CM_ "AUTOGENERATED FILE, DO NOT EDIT"

CM_ "Imported file _toyota_2017.dbc starts here"
VERSION ""

NS_ :

BS_:

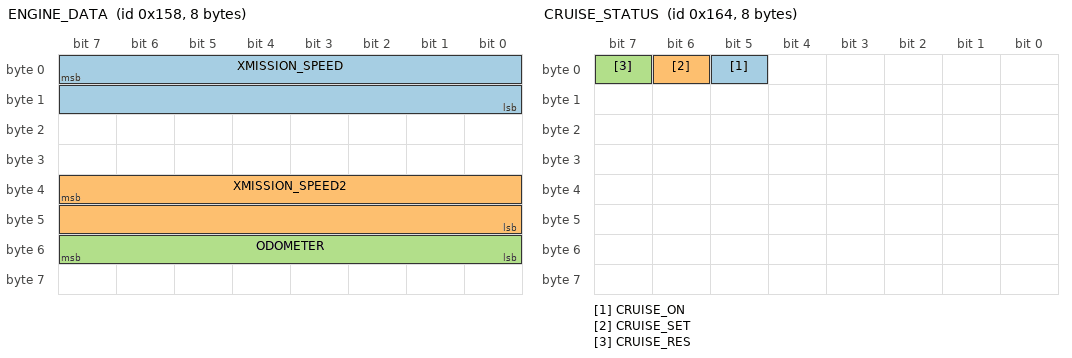
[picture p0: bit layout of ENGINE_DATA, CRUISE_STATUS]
BO_ 344 ENGINE_DATA: 8 PCM
 SG_ XMISSION_SPEED : 7|16@0+ (0.01,0) [0|250] "kph" EON
 SG_ XMISSION_SPEED2 : 39|16@0+ (0.01,0) [0|250] "kph" EON
 SG_ ODOMETER : 55|8@0+ (10,0) [0|2550] "m" XXX

BO_ 353 DSU_SPEED: 7 XXX
 SG_ FORWARD_SPEED : 15|16@0- (0.00390625,-30) [0|255] "kph" XXX

BO_ 356 CRUISE_STATUS: 8 XXX
 SG_ CRUISE_ON : 5|1@0+ (1,0) [0|1] "" XXX
 SG_ CRUISE_SET : 6|1@0+ (1,0) [0|1] "" XXX
 SG_ CRUISE_RES : 7|1@0+ (1,0) [0|1] "" XXX

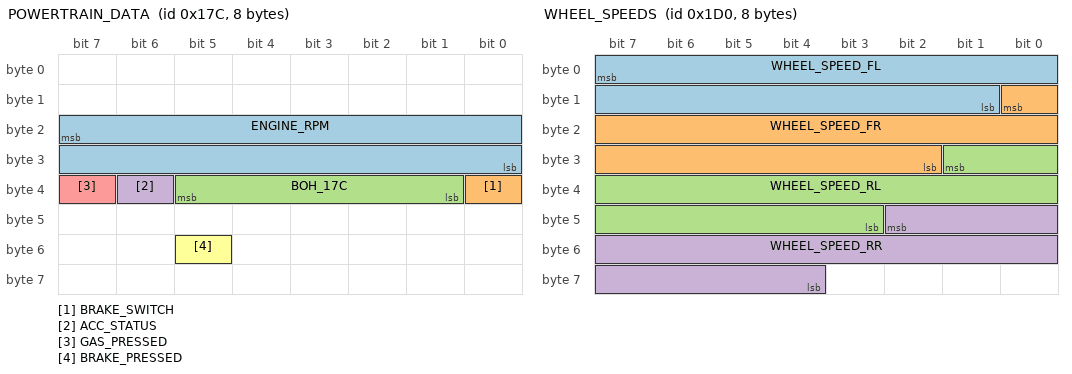
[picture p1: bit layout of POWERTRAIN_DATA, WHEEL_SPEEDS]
BO_ 380 POWERTRAIN_DATA: 8 PCM
 SG_ ENGINE_RPM : 23|16@0+ (1,0) [0|15000] "rpm" EON
 SG_ BRAKE_SWITCH : 32|1@0+ (1,0) [0|1] "" EON
 SG_ BOH_17C : 37|5@0+ (1,0) [0|1] "" EON
 SG_ ACC_STATUS : 38|1@0+ (1,0) [0|1] "" EON
 SG_ GAS_PRESSED : 39|1@0+ (1,0) [0|1] "" EON
 SG_ BRAKE_PRESSED : 53|1@0+ (1,0) [0|1] "" EON

BO_ 398 STEERING_EPS_DATA: 3 XXX
 SG_ STEERING_RATEDEG : 1|10@0+ (1,0) [0|1023] "" XXX

BO_ 452 ENGINE_RPM: 8 CGW
 SG_ RPM : 7|16@0- (0.78125,0) [0|0] "rpm" SCS

BO_ 464 WHEEL_SPEEDS: 8 VSA
 SG_ WHEEL_SPEED_FL : 7|15@0+ (0.01,0) [0|250] "kph" EON
 SG_ WHEEL_SPEED_FR : 8|15@0+ (0.01,0) [0|250] "kph" EON
 SG_ WHEEL_SPEED_RL : 25|15@0+ (0.01,0) [0|250] "kph" EON
 SG_ WHEEL_SPEED_RR : 42|15@0+ (0.01,0) [0|250] "kph" EON

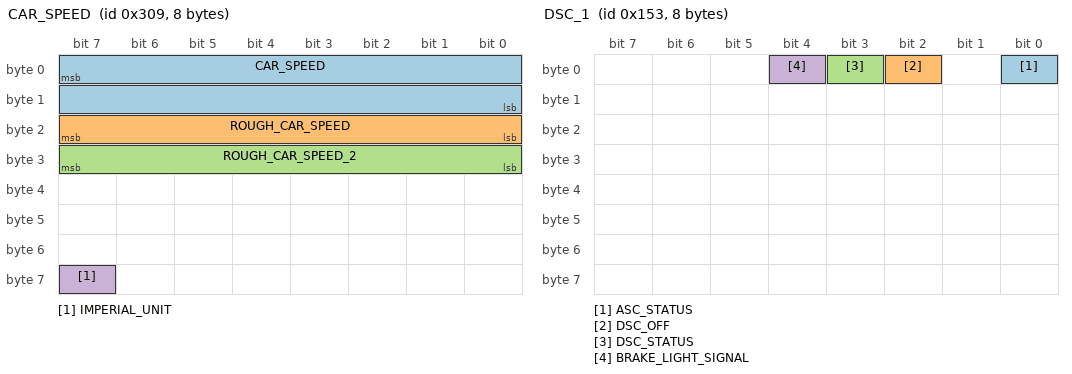
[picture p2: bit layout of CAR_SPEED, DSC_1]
BO_ 777 CAR_SPEED: 8 PCM
 SG_ CAR_SPEED : 7|16@0+ (0.01,0) [0|65535] "kph" XXX
 SG_ ROUGH_CAR_SPEED : 23|8@0+ (1,0) [0|255] "mph" XXX
 SG_ ROUGH_CAR_SPEED_2 : 31|8@0+ (1,0) [0|255] "mph" XXX
 SG_ IMPERIAL_UNIT : 63|1@0+ (1,0) [0|1] "" XXX

VAL_ 466 CRUISE_STATE 8 "active" 7 "standstill" 1 "off";
VAL_ 467 LOW_SPEED_LOCKOUT 2 "low speed locked" 1 "ok";
VAL_ 614 STATE 3 "enabled" 1 "disabled";
VAL_ 614 DIRECTION_CMD 3 "right" 2 "center" 1 "left";
VAL_ 643 STATE 0 "normal" 1 "adaptive_cruise_control" 3 "emergency_braking";
VAL_ 921 CRUISE_CONTROL_STATE 2 "disabled" 11 "hold" 10 "hold_waiting_user_cmd" 6 "enabled" 5 "faulted";
VAL_ 1042 LDA_ALERT 3 "hold with continuous beep" 2 "LDA unavailable" 1 "hold" 0 "none";
VAL_ 1042 BARRIERS 3 "both" 2 "right" 1 "left" 0 "none";
VAL_ 1042 RIGHT_LINE 3 "orange" 2 "faded" 1 "solid" 0 "none";
VAL_ 1042 LEFT_LINE 3 "orange" 2 "faded" 1 "solid" 0 "none";
VAL_ 1553 UNITS 1 "km" 2 "miles";
VAL_ 1556 TURN_SIGNALS 3 "none" 2 "right" 1 "left";
VAL_ 1161 TSGN1 1 "speed sign" 0 "none";
VAL_ 1161 TSGN2 1 "speed sign" 0 "none";
VAL_ 1161 SPLSGN2 15 "conditional blank" 4 "wet road" 5 "rain" 0 "none";
VAL_ 1162 TSGN3 0 "none" 1 "speed sign" 2 "0 unlimited" 7 "unlimited" 16 "highway" 17 "no highway" 18 "motorway" 19 "no motorway" 20 "in city" 21 "outside city" 22 "pedestrian area" 23 "no pedestrian area" 65 "no overtaking left" 66 "no overtaking right" 67 "overtaking allowed again" 129 "no entry";
VAL_ 1162 SPLSGN3 15 "conditional blank" 4 "wet road" 5 "rain" 0 "none";

CM_ "CHFFR_METRIC 37 STEER_ANGLE STEER_ANGLE 0.36 180";

CM_ "toyota_corolla_2017_pt.dbc starts here"

BO_ 339 DSC_1: 8 XXX
 SG_ ASC_STATUS : 0|1@1+ (1,0) [0|3] "" XXX
 SG_ DSC_OFF : 2|1@1+ (1,0) [0|3] "" XXX
 SG_ DSC_STATUS : 3|1@0+ (1,0) [0|3] "" XXX
 SG_ BRAKE_LIGHT_SIGNAL : 4|1@0+ (1,0) [0|3] "" XXX

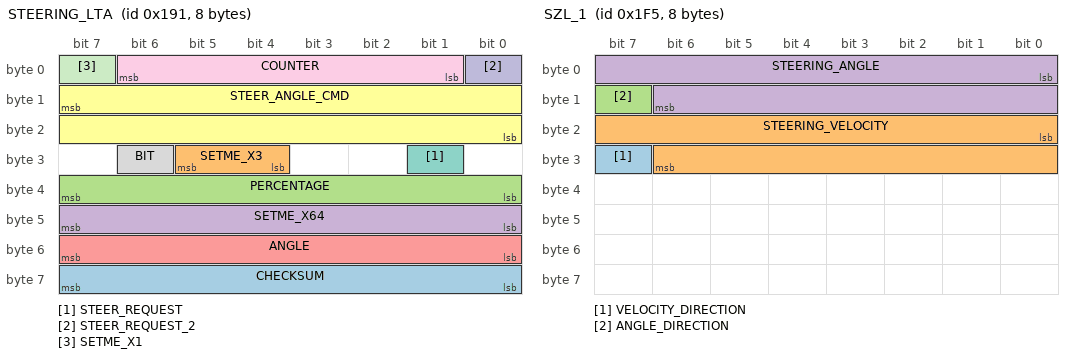
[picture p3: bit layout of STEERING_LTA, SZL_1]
BO_ 401 STEERING_LTA: 8 XXX
 SG_ CHECKSUM : 63|8@0+ (1,0) [0|255] "" XXX
 SG_ SETME_X3 : 29|2@0+ (1,0) [0|3] "" XXX
 SG_ PERCENTAGE : 39|8@0+ (1,0) [0|255] "" XXX
 SG_ SETME_X64 : 47|8@0+ (1,0) [0|255] "" XXX
 SG_ ANGLE : 55|8@0- (0.5,0) [0|255] "" XXX
 SG_ STEER_ANGLE_CMD : 15|16@0- (0.0573,0) [-540|540] "" XXX
 SG_ STEER_REQUEST : 25|1@0+ (1,0) [0|1] "" XXX
 SG_ BIT : 30|1@0+ (1,0) [0|1] "" XXX
 SG_ COUNTER : 6|6@0+ (1,0) [0|255] "" XXX
 SG_ STEER_REQUEST_2 : 0|1@0+ (1,0) [0|1] "" XXX
 SG_ SETME_X1 : 7|1@0+ (1,0) [0|1] "" XXX

BO_ 501 SZL_1: 8 XXX
 SG_ VELOCITY_DIRECTION : 31|1@0+ (1,0) [0|1] "" XXX
 SG_ STEERING_VELOCITY : 16|15@1+ (0.045,0) [0|1] "deg/s" XXX
 SG_ ANGLE_DIRECTION : 15|1@0+ (1,0) [0|1] "" XXX
 SG_ STEERING_ANGLE : 0|15@1+ (0.045,0) [0|1] "deg" XXX

BO_ 548 BRAKE_MODULE: 8 XXX
 SG_ BRAKE_PRESSURE : 43|12@0+ (1,0) [0|4047] "" XXX
 SG_ BRAKE_PRESSED : 5|1@0+ (1,0) [0|1] "" XXX

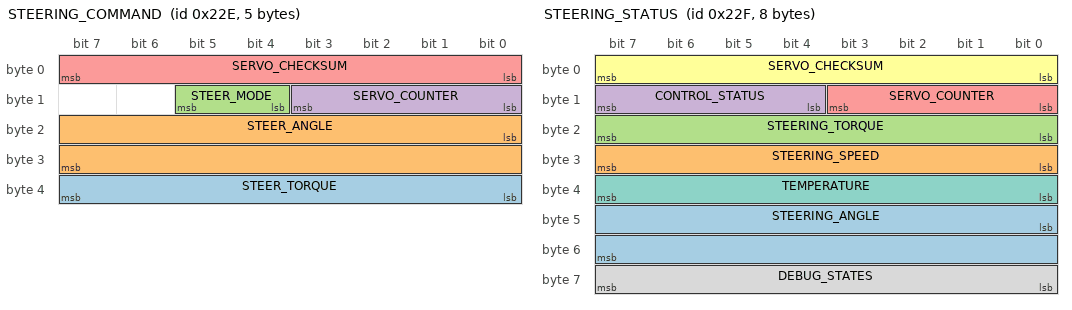
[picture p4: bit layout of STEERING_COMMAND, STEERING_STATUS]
BO_ 558 STEERING_COMMAND: 5 EON
 SG_ STEER_TORQUE : 32|8@1- (0.125,0) [-16|15.875] "Nm" EPAS
 SG_ STEER_ANGLE : 16|16@1- (0.125,0) [-4096|4095.875] "deg" EPAS
 SG_ STEER_MODE : 12|2@1+ (1,0) [0|3] "" EPAS
 SG_ SERVO_COUNTER : 8|4@1+ (1,0) [0|15] "" EPAS
 SG_ SERVO_CHECKSUM : 0|8@1+ (1,0) [0|255] "" EPAS

BO_ 559 STEERING_STATUS: 8 EPAS
 SG_ STEERING_ANGLE : 40|16@1- (0.125,0) [-4096|4095.875] "deg" EON
 SG_ STEERING_SPEED : 24|8@1- (0.015625,0) [-2|1.984375] "rev/s" EON
 SG_ STEERING_TORQUE : 16|8@1- (0.125,0) [-16|15.875] "Nm" EON
 SG_ CONTROL_STATUS : 12|4@1+ (1,0) [0|15] "" EON
 SG_ SERVO_COUNTER : 8|4@1+ (1,0) [0|15] "" EON
 SG_ SERVO_CHECKSUM : 0|8@1+ (1,0) [0|255] "" EON
 SG_ TEMPERATURE : 32|8@1+ (1,-60) [-60|195] "C" EON
 SG_ DEBUG_STATES : 56|8@1+ (1,0) [0|255] "" EON

CM_ SG_ 548 BRAKE_PRESSURE "seems prop to pedal force";
CM_ SG_ 548 BRAKE_POSITION "seems proportional to pedal displacement, unclear the max value of 0x1c8";
CM_ SG_ 558 STEER_TORQUE "Steering torque request";
CM_ SG_ 558 STEER_ANGLE "Steering relative angle request for internal close loop controller";
CM_ SG_ 558 STEER_MODE "Control mode request. 
Off - instant 0 torque.
TorqueControl - use steer_torque
RelativeControl - use steer_angle as relative target and steer_torque as feedforward. 
SoftOff - ramp torque to 0 in 1s. 
Command Off after SoftOff to re-enable control.";
CM_ SG_ 558 COUNTER "Rolling counter";
CM_ SG_ 558 CHECKSUM "8bit sum of all bytes and message id";
CM_ SG_ 559 STEERING_ANGLE "Steering angle calculated from motor position sensor";
CM_ SG_ 559 STEERING_SPEED "Steering speed calculated from motor position sensor";
CM_ SG_ 559 STEERING_TORQUE "Motor torque calculated at the steering";
CM_ SG_ 559 CONTROL_STATUS "Bitwise states: bit0 - sensored torque control is enabled, bit1 - sensor feedback enabled, bit2 - openloop soft off active, bit3 - internal closeloop mode enabled";
CM_ SG_ 559 COUNTER "Rolling counter";
CM_ SG_ 559 CHECKSUM "8bit sum of all bytes and message id";
CM_ SG_ 559 TEMPERATURE "Motor PCB temperature";
CM_ SG_ 559 DEBUG_STATES "Bitwise status. Refer to source";
VAL_ 558 STEER_MODE 0 "Off" 1 "TorqueControl" 2 "RelativeControl" 3 "SoftOff" ;
